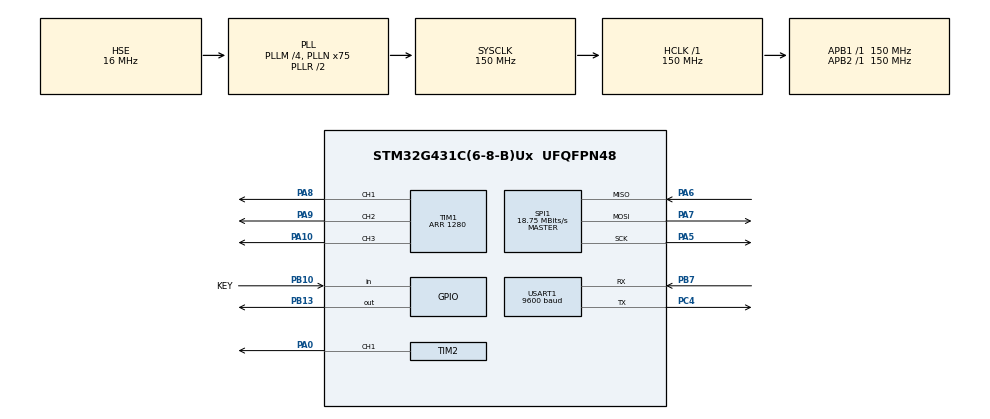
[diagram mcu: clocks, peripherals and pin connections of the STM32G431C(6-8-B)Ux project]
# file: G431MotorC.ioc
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Mcu.Family=STM32G4
Mcu.Name=STM32G431C(6-8-B)Ux
Mcu.Package=UFQFPN48
NVIC.PriorityGroup=NVIC_PRIORITYGROUP_4
PA0.Signal=S_TIM2_CH1
PA10.Signal=S_TIM1_CH3
PA13.Mode=Serial_Wire
PA13.Signal=SYS_JTMS-SWDIO
PA14.Mode=Serial_Wire
PA14.Signal=SYS_JTCK-SWCLK
PA5.Mode=Full_Duplex_Master
PA5.Signal=SPI1_SCK
PA6.Mode=Full_Duplex_Master
PA6.Signal=SPI1_MISO
PA7.Mode=Full_Duplex_Master
PA7.Signal=SPI1_MOSI
PA8.Signal=S_TIM1_CH1
PA9.Signal=S_TIM1_CH2
PB10.GPIO_Label=KEY
PB10.GPIO_Mode=GPIO_MODE_INPUT
PB10.GPIO_PuPd=GPIO_PULLUP
PB10.Signal=GPIO_Input
PB13.Signal=GPIO_Output
PB7.Mode=Asynchronous
PB7.Signal=USART1_RX
PC4.Mode=Asynchronous
PC4.Signal=USART1_TX
PF0-OSC_IN.Mode=HSE-External-Oscillator
PF0-OSC_IN.Signal=RCC_OSC_IN
PF1-OSC_OUT.Mode=HSE-External-Oscillator
PF1-OSC_OUT.Signal=RCC_OSC_OUT
ProjectManager.HeapSize=0x200
ProjectManager.StackSize=0x400
ProjectManager.TargetToolchain=MDK-ARM V5.32
RCC.ADC12Freq_Value=150000000
RCC.AHBFreq_Value=150000000
RCC.APB1Freq_Value=150000000
RCC.APB1TimFreq_Value=150000000
RCC.APB2Freq_Value=150000000
RCC.APB2TimFreq_Value=150000000
RCC.CortexFreq_Value=150000000
RCC.EXTERNAL_CLOCK_VALUE=12288000
RCC.HCLKFreq_Value=150000000
RCC.HSE_VALUE=16000000
RCC.HSI48_VALUE=48000000
RCC.HSI_VALUE=16000000
RCC.LSE_VALUE=32768
RCC.PLLM=RCC_PLLM_DIV4
RCC.PLLN=75
RCC.PLLSourceVirtual=RCC_PLLSOURCE_HSE
RCC.SYSCLKFreq_VALUE=150000000
RCC.SYSCLKSource=RCC_SYSCLKSOURCE_PLLCLK
RCC.USBFreq_Value=150000000
RCC.VCOOutputFreq_Value=300000000
SH.S_TIM1_CH1.0=TIM1_CH1,PWM Generation1 CH1
SH.S_TIM1_CH2.0=TIM1_CH2,PWM Generation2 CH2
SH.S_TIM1_CH3.0=TIM1_CH3,Output Compare3 CH3
SH.S_TIM2_CH1.0=TIM2_CH1,PWM Generation1 CH1
SPI1.BaudRatePrescaler=SPI_BAUDRATEPRESCALER_8
SPI1.CLKPhase=SPI_PHASE_2EDGE
SPI1.CLKPolarity=SPI_POLARITY_HIGH
SPI1.CalculateBaudRate=18.75 MBits/s
SPI1.DataSize=SPI_DATASIZE_16BIT
SPI1.Direction=SPI_DIRECTION_2LINES
SPI1.Mode=SPI_MODE_MASTER
SPI1.VirtualType=VM_MASTER
TIM1.Channel-Output\ Compare3\ CH3=TIM_CHANNEL_3
TIM1.Channel-PWM\ Generation1\ CH1=TIM_CHANNEL_1
TIM1.Channel-PWM\ Generation2\ CH2=TIM_CHANNEL_2
TIM1.PeriodNoDither=1280
TIM2.Channel-PWM\ Generation1\ CH1=TIM_CHANNEL_1
TIM2.PeriodNoDither=800 - 1
TIM2.Prescaler=150-1
USART1.BaudRate=9600
USART1.VirtualMode-Asynchronous=VM_ASYNC
VP_SYS_VS_DBSignals.Mode=DisableDeadBatterySignals
VP_TIM1_VS_ClockSourceINT.Mode=Internal
board=custom

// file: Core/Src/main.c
/* USER CODE BEGIN Header */
/**
  ******************************************************************************
  * @file           : main.c
  * @brief          : Main program body
  ******************************************************************************
  * @attention
  *
  * Copyright (c) 2024 STMicroelectronics.
  * All rights reserved.
  *
  * This software is licensed under terms that can be found in the LICENSE file
  * in the root directory of this software component.
  * If no LICENSE file comes with this software, it is provided AS-IS.
  *
  ******************************************************************************
  */
/* USER CODE END Header */
#include "main.h"
#include "spi.h"
#include "tim.h"
#include "usart.h"
#include "gpio.h"

/* USER CODE BEGIN Includes */
#include "MT6835Sensor.h"
/* USER CODE END Includes */

void SystemClock_Config(void);

int main(void)
{

  /* MCU Configuration--------------------------------------------------------*/

  /* Reset of all peripherals, Initializes the Flash interface and the Systick. */
  HAL_Init();

  /* Configure the system clock */
  SystemClock_Config();

  /* Initialize all configured peripherals */
  MX_GPIO_Init();
  MX_TIM1_Init();
  MX_TIM2_Init();
  MX_USART1_UART_Init();
  MX_SPI1_Init();

  /* Infinite loop */
  /* USER CODE BEGIN WHILE */
  while (1)
  {
      Read_AngleReg();
    /* USER CODE END WHILE */

  }
}

void SystemClock_Config(void)
{
  RCC_OscInitTypeDef RCC_OscInitStruct = {0};
  RCC_ClkInitTypeDef RCC_ClkInitStruct = {0};

  /** Configure the main internal regulator output voltage
  */
  HAL_PWREx_ControlVoltageScaling(PWR_REGULATOR_VOLTAGE_SCALE1);

  /** Initializes the RCC Oscillators according to the specified parameters
  * in the RCC_OscInitTypeDef structure.
  */
  RCC_OscInitStruct.OscillatorType = RCC_OSCILLATORTYPE_HSE;
  RCC_OscInitStruct.HSEState = RCC_HSE_ON;
  RCC_OscInitStruct.PLL.PLLState = RCC_PLL_ON;
  RCC_OscInitStruct.PLL.PLLSource = RCC_PLLSOURCE_HSE;
  RCC_OscInitStruct.PLL.PLLM = RCC_PLLM_DIV4;
  RCC_OscInitStruct.PLL.PLLN = 75;
  RCC_OscInitStruct.PLL.PLLP = RCC_PLLP_DIV2;
  RCC_OscInitStruct.PLL.PLLQ = RCC_PLLQ_DIV2;
  RCC_OscInitStruct.PLL.PLLR = RCC_PLLR_DIV2;
  if (HAL_RCC_OscConfig(&RCC_OscInitStruct) != HAL_OK)
  {
    Error_Handler();
  }

  /** Initializes the CPU, AHB and APB buses clocks
  */
  RCC_ClkInitStruct.ClockType = RCC_CLOCKTYPE_HCLK|RCC_CLOCKTYPE_SYSCLK
                              |RCC_CLOCKTYPE_PCLK1|RCC_CLOCKTYPE_PCLK2;
  RCC_ClkInitStruct.SYSCLKSource = RCC_SYSCLKSOURCE_PLLCLK;
  RCC_ClkInitStruct.AHBCLKDivider = RCC_SYSCLK_DIV1;
  RCC_ClkInitStruct.APB1CLKDivider = RCC_HCLK_DIV1;
  RCC_ClkInitStruct.APB2CLKDivider = RCC_HCLK_DIV1;

  if (HAL_RCC_ClockConfig(&RCC_ClkInitStruct, FLASH_LATENCY_4) != HAL_OK)
  {
    Error_Handler();
  }
}

void Error_Handler(void)
{
  __disable_irq();
  while (1)
  {
  }
}
